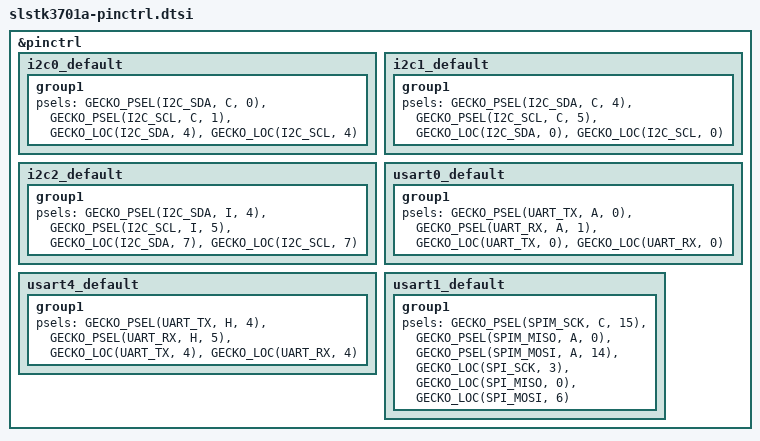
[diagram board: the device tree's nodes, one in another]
/*
 * Copyright (c) 2023 Antmicro <www.antmicro.com>
 *
 * SPDX-License-Identifier: Apache-2.0
 */

#include <zephyr/dt-bindings/pinctrl/gecko-pinctrl-s1.h>

&pinctrl {
	i2c0_default: i2c0_default {
		group1 {
			psels = <GECKO_PSEL(I2C_SDA, C, 0)>,
				<GECKO_PSEL(I2C_SCL, C, 1)>,
				<GECKO_LOC(I2C_SDA, 4)>,
				<GECKO_LOC(I2C_SCL, 4)>;
		};
	};

	i2c1_default: i2c1_default {
		group1 {
			psels = <GECKO_PSEL(I2C_SDA, C, 4)>,
				<GECKO_PSEL(I2C_SCL, C, 5)>,
				<GECKO_LOC(I2C_SDA, 0)>,
				<GECKO_LOC(I2C_SCL, 0)>;
		};
	};

	i2c2_default: i2c2_default {
		group1 {
			psels = <GECKO_PSEL(I2C_SDA, I, 4)>,
				<GECKO_PSEL(I2C_SCL, I, 5)>,
				<GECKO_LOC(I2C_SDA, 7)>,
				<GECKO_LOC(I2C_SCL, 7)>;
		};
	};

	/* configuration for usart0 device, default state - operating as UART */
	usart0_default: usart0_default {
		group1 {
			psels = <GECKO_PSEL(UART_TX, A, 0)>,
				<GECKO_PSEL(UART_RX, A, 1)>,
				<GECKO_LOC(UART_TX, 0)>,
				<GECKO_LOC(UART_RX, 0)>;
		};
	};

	usart4_default: usart4_default {
		group1 {
			psels = <GECKO_PSEL(UART_TX, H, 4)>,
				<GECKO_PSEL(UART_RX, H, 5)>,
				<GECKO_LOC(UART_TX, 4)>,
				<GECKO_LOC(UART_RX, 4)>;
		};
	};

	usart1_default: usart1_default {
		group1 {
			psels = <GECKO_PSEL(SPIM_SCK, C, 15)>,
				<GECKO_PSEL(SPIM_MISO, A, 0)>,
				<GECKO_PSEL(SPIM_MOSI, A, 14)>,
				<GECKO_LOC(SPI_SCK, 3)>,
				<GECKO_LOC(SPI_MISO, 0)>,
				<GECKO_LOC(SPI_MOSI, 6)>;
		};
	};
};
